# efuse_interface_ctrl: IP-XACT component
VLNV tenstorrent.com:ocah:efuse_interface_ctrl:1.0

## Address spaces and blocks
efuse_interface_ctrl_mmap.efuse_interface_ctrl: base 'h0, range 'h24, width 32

## Registers
Registers are 32-bit, read-write, reset 0x0 unless marked. A register's access mark holds for its fields unless they carry their own. Offsets are from the block's base; lines under a group give offsets from that group; [hi:lo] are bit positions; {n}, {i} and the like mark numbered series; 'fields as' and 'values as' point back to an identical list; <NAME> marks a mode.

## efuse_interface_ctrl_mmap.efuse_interface_ctrl — Program and read command, address, data, status, and timeout registers for the eFuse interface.
Base 0x00000000
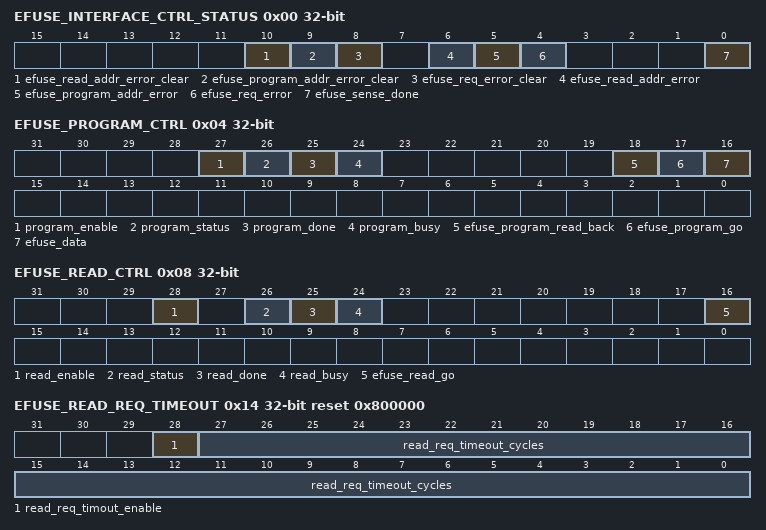
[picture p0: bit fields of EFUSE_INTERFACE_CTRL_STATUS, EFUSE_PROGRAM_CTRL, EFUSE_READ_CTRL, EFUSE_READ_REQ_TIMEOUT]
0x00 EFUSE_INTERFACE_CTRL_STATUS access per field (reset mask 0x770) — eFuse interface status and error-clear register. Reports the sense-done flag and request/address error conditions, and provides write-1 strobes to clear those errors.
  [10] efuse_read_addr_error_clear wo — Clears the read out of bounds error bit (efuse_read_addr_error) in efuse_ctrl_status
  [9] efuse_program_addr_error_clear wo — Clears the program out of bounds error bit (efuse_program_addr_error) in efuse_ctrl_status
  [8] efuse_req_error_clear wo — Clears the blocked request error bit in efuse_ctrl_status
  [6] efuse_read_addr_error ro — Indicates that an invalid eFuse read address was used (address exceeds the implemented eFuse size). The error must be cleared by writing 1 to efuse_read_addr_error_clear.
  [5] efuse_program_addr_error ro — Indicates that an invalid eFuse program address was used (address exceeds the implemented eFuse size). The error must be cleared by writing 1 to efuse_program_addr_error_clear.
  [4] efuse_req_error ro — Indicates that the eFuse was blocked because of either read or a program lock. The error must be cleared by writing 1 to efuse_req_error_clear to this register
  [0] efuse_sense_done ro — Indicates if the eFuse state machine has completed
0x04 EFUSE_PROGRAM_CTRL access per field — eFuse program control and status. Configures the program data, triggers a program of the bit at EFUSE_PROGRAM_ADDR (optionally with read-back), and reports program progress and completion status.
  [27] program_enable rw — When set, enables the program request
  [26] program_status ro — 0: No Error. 1: Error
  [25] program_done ro — When set, the program has completed, the status of which is in program_status
  [24] program_busy ro — When set, the program is in progress
  [18] efuse_program_read_back rw — When set, trigger a read back after a program
  [17] efuse_program_go rw — When set, triggers a program to the eFuse. This will be ignored if the lock bit is set
  [16] efuse_data rw — Data to program to eFuse. If this bit is 0, the program request will be ignored
0x08 EFUSE_READ_CTRL access per field — eFuse read control and status. Triggers a read of the word at EFUSE_READ_ADDR and reports read progress and completion status.
  [28] read_enable rw — When set, enables the read request
  [26] read_status ro — 0: No Error. 1: Error. Set when read_go is asserted while read is not enabled, the address is out of bounds, or the read request times out.
  [25] read_done ro — When set, the read has completed, the status of which is in read_status
  [24] read_busy ro — When set, the read is in progress
  [16] efuse_read_go rw — When set, triggers a read to efuse.
0x0C EFUSE_PROGRAM_INTERFACE_READ_DATA ro — Read data captured through the program interface. Hardware debug only; valid only while the program interface state machine is in its capture-data state.
  [31:0] dout — Read Data from eFuse through program interface. This field is only valid when the efuse programming interface is utilized to burn the efuse IP and only when the state machine is during ST_CAPTUER_DATA state. Hardware debug only
0x10 EFUSE_READ_INTERFACE_READ_DATA ro — Read data returned through the eFuse read interface.
  [31:0] dout — Read Data from eFuse through READ interface.
0x14 EFUSE_READ_REQ_TIMEOUT reset 0x800000 — Read interface timeout configuration. Sets the number of cycles the read interface waits for a SHIM response and enables the read timeout.
  [28] read_req_timout_enable — Enable timeout on read interface
  [27:0] read_req_timeout_cycles — Number of cycles the read interface will wait for a response from the shim. At 100MHz this can count ~= 2.5 seconds.
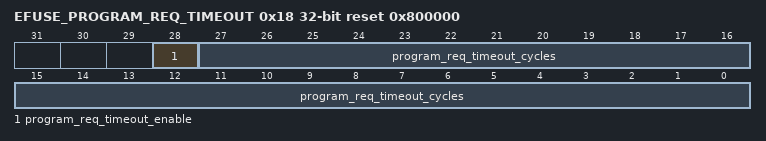
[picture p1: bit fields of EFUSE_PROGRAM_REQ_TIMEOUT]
0x18 EFUSE_PROGRAM_REQ_TIMEOUT reset 0x800000 — Program interface timeout configuration. Sets the number of cycles the program interface waits for a SHIM response and enables the program timeout.
  [28] program_req_timeout_enable — Enable timeout on program interface.
  [27:0] program_req_timeout_cycles — Number of cycles the program interface will wait for a response from the shim. At 100MHz this can count ~= 2.5 seconds.
0x1C EFUSE_PROGRAM_ADDR — Bit address for the next program. Set it before EFUSE_PROGRAM_CTRL.efuse_program_go.
  [31:0] efuse_addr — Bit address to program. Writing this register does not check the address; a program started with an address at or beyond the implemented eFuse size is not issued and sets efuse_program_addr_error.
0x20 EFUSE_READ_ADDR — Bit address for the next read. Set it before EFUSE_READ_CTRL.efuse_read_go.
  [31:0] efuse_addr — Bit address of the word to read. Writing this register does not check the address; a read started with an address at or beyond the implemented eFuse size is not issued and sets efuse_read_addr_error.

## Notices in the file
SPDX-License-Identifier: Apache-2.0
SPDX-FileCopyrightText: 2026 Tenstorrent USA, Inc.
